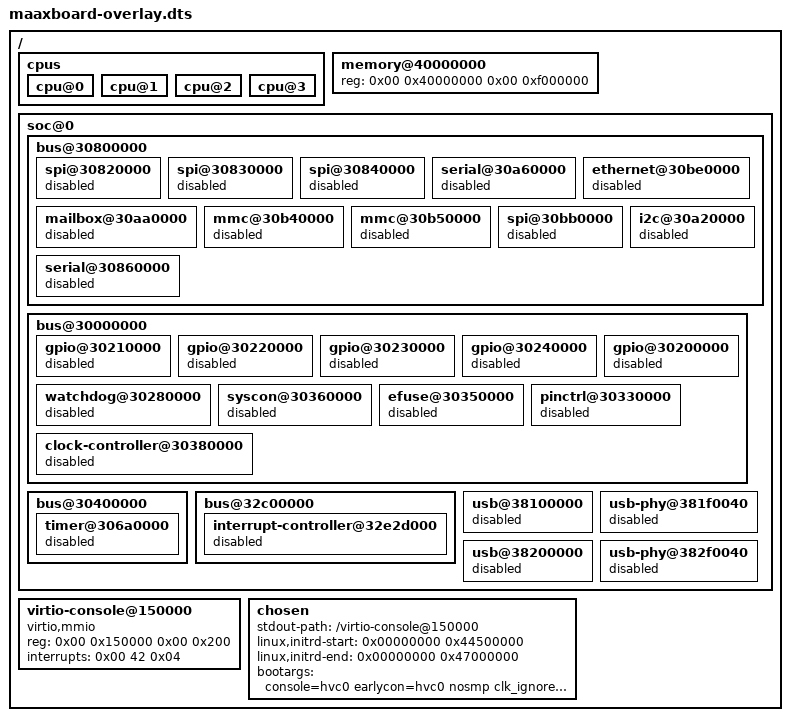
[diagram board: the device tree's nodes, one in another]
/ {

    cpus {

        cpu@0 {
            /delete-property/ cpu-idle-states;
        };

        cpu@1 {
            /delete-property/ cpu-idle-states;
        };

        cpu@2 {
            /delete-property/ cpu-idle-states;
        };

        cpu@3 {
            /delete-property/ cpu-idle-states;
        };

        /delete-node/ idle-states;

    };

    memory@40000000 {
        device_type = "memory";
        reg = <0x00 0x40000000 0x00 0xf000000>;
    };

    /delete-node/ reserved-memory;

    soc@0 {

        bus@30800000 {

            spi@30820000 {
                status = "disabled";
            };

            spi@30830000 {
                status = "disabled";
            };

            spi@30840000 {
                status = "disabled";
            };

            serial@30a60000 {
                status = "disabled";
            };

            ethernet@30be0000 {
                status = "disabled";
            };

            mailbox@30aa0000 {
                status = "disabled";
            };

            mmc@30b40000 {
                status = "disabled";
            };

            mmc@30b50000 {
                status = "disabled";
            };

            spi@30bb0000 {
                status = "disabled";
            };

            i2c@30a20000 {
                status = "disabled";
            };

            serial@30860000 {
                status = "disabled";
            };

        };

        bus@30000000 {

            gpio@30210000 {
                status = "disabled";
            };

            gpio@30220000 {
                status = "disabled";
            };

            gpio@30230000 {
                status = "disabled";
            };

            gpio@30240000 {
                status = "disabled";
            };

            gpio@30200000 {
                status = "disabled";
            };

            watchdog@30280000 {
                status = "disabled";
            };

            syscon@30360000 {
                status = "disabled";
		    };

            efuse@30350000 {
                status = "disabled";
		    };

            pinctrl@30330000 {
                status = "disabled";
		    };

            clock-controller@30380000 {
                status = "disabled";
            };
        };

        bus@30400000 {
            timer@306a0000 {
                status = "disabled";
            };
        };

        bus@32c00000 {
			interrupt-controller@32e2d000 {
                status = "disabled";
            };
        };

        usb@38100000 {
            status = "disabled";
        };

        usb-phy@381f0040 {
            status = "disabled";
        };

        usb@38200000 {
            status = "disabled";
        };

        usb-phy@382f0040 {
            status = "disabled";
        };
    };

    virtio-console@150000 {
        compatible = "virtio,mmio";
        reg = <0x00 0x150000 0x00 0x200>;
        interrupts = <0x00 42 0x04>;
    };


    chosen {
        stdout-path = "/virtio-console@150000";
        linux,initrd-start = <0x00000000 0x44500000>;
        linux,initrd-end =   <0x00000000 0x47000000>;

        /* nosmp: Ensure single core. */
        bootargs = "console=hvc0 earlycon=hvc0 nosmp clk_ignore_unused";
    };

};
